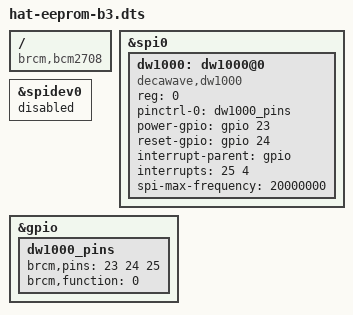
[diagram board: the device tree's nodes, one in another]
/dts-v1/;
/plugin/;

/ {
        compatible = "brcm,bcm2708";

        fragment@0 {
                target = <&spi0>;
                __overlay__ {
                        status = "okay";
                };
        };

        fragment@1 {
                target = <&spidev0>;
                __overlay__ {
                        status = "disabled";
                };
        };

        fragment@2 {
                target = <&gpio>;
                __overlay__ {
                        dw1000_pins: dw1000_pins {
                                brcm,pins = <23 24 25>;
                                brcm,function = <0>;
                        };
                };
        };

        fragment@3 {
                target = <&spi0>;
                __overlay__ {
                        #address-cells = <1>;
                        #size-cells = <0>;
                        dw1000: dw1000@0 {
                                compatible = "decawave,dw1000";
                                reg = <0>;
                                pinctrl-names = "default";
                                pinctrl-0 = <&dw1000_pins>;
                                power-gpio = <&gpio 23 0>;
                                reset-gpio = <&gpio 24 6>;
                                interrupt-parent = <&gpio>;
                                interrupts = <25 4>;
                                spi-max-frequency = <20000000>;
                        };
                };
        };
        __overrides__ {
                dw1000_eui = <&dw1000>,"decawave,eui64#0";
        };
};

